# FM33L0XX register map
File version: 1.0
CPU: SC000 r1p0, little endian, no MPU, no FPU, 3 interrupt priority bits
Registers are 32-bit, read-write, reset 0x0 unless marked. A register's access mark holds for its fields unless they carry their own. Offsets are from the block's base; [hi:lo] are bit positions.

## SPI1 — SPI Serial Peripheral Interface
Base 0x40010840
Same registers: SPI2 0x40010880
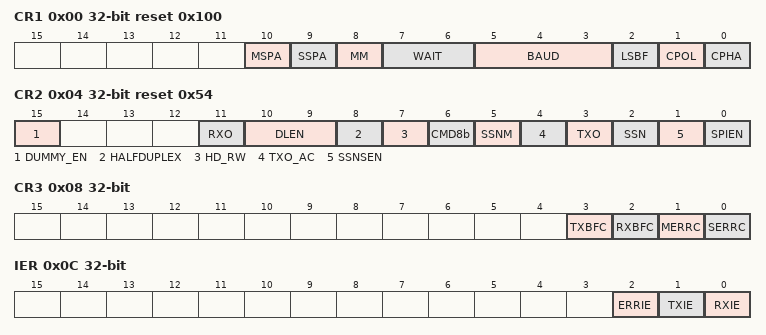
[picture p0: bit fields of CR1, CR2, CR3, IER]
0x00 CR1 reset 0x100 — SPI Control Register
  [10] MSPA — Master Sampling Position Adjustment, Master MISO
    0=NO_DELAY (NO_DELAY at master MISO); 1=0.5SCK_DELAY (0.5SCK delay at master MISO)
  [9] SSPA — Slave Sending Position Adjustment, Slave MISO
    0=NO_ADJUST (NO_AHEAD at slave MISO); 1=0.5SCK (0.5SCK ahead at slave MISO)
  [8] MM — Master/Slave mode select
    0=SLAVE (slave mode); 1=Master mode
  [7:6] WAIT — WAIT clock setting at master mode,(1+wait) clock
  [5:3] BAUD — BAUD setting
    0=fPCLK /2 (only Master mode); 1=fPCLK/4 (only Master mode); 2=fPCLK/8 (only Master mode); 3=fPCLK/16 (only Master mode); 4=fPCLK/32 (only Master mode); 5=fPCLK/64 (only Master mode); 6=fPCLK/128 (only Master mode); 7=fPCLK/256 (only Master mode)
  [2] LSBF — Frame format bit
    0=MSB (MSB first); 1=LSB (LSB first)
  [1] CPOL — Clock polarity bit
    0=LOW (Idle clock voltage is low); 1=HIGH (Idle clock voltage is low)
  [0] CPHA — Clock phase bit
    0=FIRST (capture at First edge); 1=SECOND (capture at Second edge)
0x04 CR2 reset 0x54 — control Register2
  [15] DUMMY_EN
    0=DISABLE (disable dummy); 1=ENABLE (enable dummy)
  [11] RXO — rx only mode
    0=DISABLE (disable rx only mode); 1=ENABLE (enable rx only mode)
  [10:9] DLEN — data len
    0=8bit (len 8 bit); 1=16bit (len 16 bit); 2=24bit (len 24 bit); 3=32bit (len 32 bit)
  [8] HALFDUPLEX — transfer mode
    0=DUPLEX MODE; 1=HALFDUPLEX MODE
  [7] HD_RW — HALFDUPLEX WRITE OR READ
    0=HALFDUPLEX WRITE; 1=HALFDUPLEX READ
  [6] CMD8b — whether cmd 8 bit
    0=CMD_DLEN; 1=CMD 8 BIT
  [5] SSNM — SSN keep low/high after sending 8bit data at master mode
    0=LOW (SSN keep low after sending 8bit data at master mode); 1=HIGH (SSN keep hign after sending 8bit data at master mode)
  [4] TXO_AC — auto clear at tx_only mode enable
    0=DISABLE (disable auto clear at tx_only mode enable); 1=ENABLE (enable auto clear at tx_only mode enable)
  [3] TXO — TX only
    0=DISABLE (disable tx_only mode); 1=ENABLE (enable tx_only mode)
  [2] SSN — SSN control bit
    0=LOW (SSN output is low voltage); 1=HIGH (SSN output is high voltage)
  [1] SSNSEN — SSN controled by software at master mode
    0=AUTO_OUTPUT (SSN auto output at master mode); 1=SOFTWARE (SSN output controled by software at master mode)
  [0] SPIEN — SPI enable bit
    0=DISABLE (SPI disable); 1=ENABLE (SPI enable)
0x08 CR3 — control Register3
  [3] TXBFC — Transmit Buffer Clear bit,write 1 to clear
  [2] RXBFC — Receive Buffer Clear bit,write 1 to clear
  [1] MERRC — Master Error Clear bit,write 1 to clear
  [0] SERRC — Slave Error Clear bit,write 1 to clear
0x0C IER — SPI interrupt enable Register
  [2] ERRIE — error interrupt enable bit
    0=DISABLE (ERRIE DISABLE); 1=ENABLE (ERRIE ENABLE)
  [1] TXIE — transmit interrupt enable bit
    0=DISABLE (TXIE DISABLE); 1=ENABLE (TXIE ENABLE)
  [0] RXIE — receive interrupt enable bit
    0=DISABLE (RXIE DISABLE); 1=ENABLE (RXIE ENABLE)
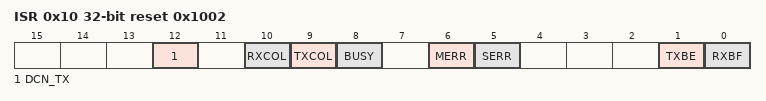
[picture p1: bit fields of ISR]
0x10 ISR reset 0x1002 — SPI interrupt flag Register
  [12] DCN_TX — DCN_TX MODE
    0=CMD (DCN_CMD); 1=DATA (DCN_DATA)
  [10] RXCOL — RX Buffer overflow,write 1 to clear
    0=NO_RXOV; 1=RXOV
  [9] TXCOL — TX Buffer overflow,write 1 to clear
    0=NO_TXOV; 1=TXOV
  [8] BUSY ro — busy flag
    0=NO_BUSY; 1=BUSY
  [6] MERR ro — Master Error Flag
    0=NO_MERR; 1=MERR
  [5] SERR ro — Slave Error Flag
    0=NO_SERR; 1=SERR
  [1] TXBE ro — TX Buffer Empty,write TXBUF clear this bit
    0=TXBE_FULL (tx buff full); 1=TXBE_EMPTY (tx buff empty)
  [0] RXBF ro — RX Buffer Full,read RXBUF clear this bit
    0=RXBF_EMPTY (rx buff empty); 1=RXBF_FULL (rx buff full)
0x14 SPI_TXBUF — SPI TX buffer Register
  [31:0] TXBUF wo — TXBUF 8BIT
0x18 SPI_RXBUF — SPI RX buffer Register
  [31:0] RXBUF ro — RXBUF 8bit
